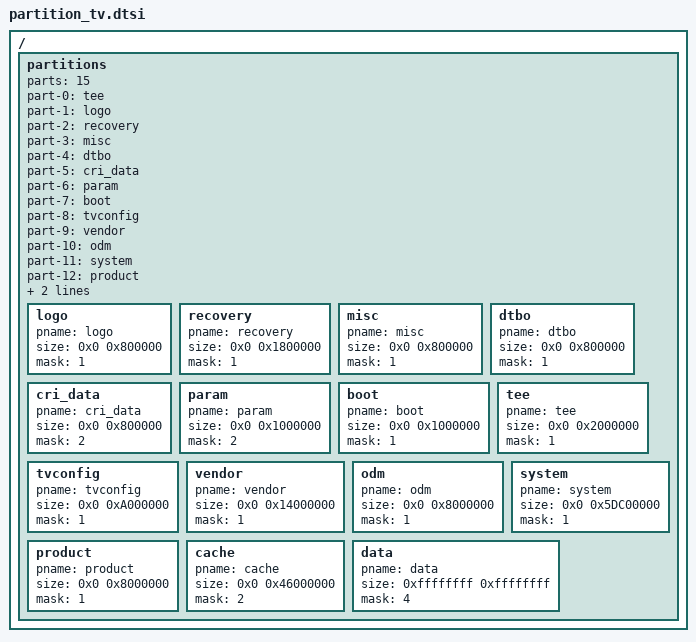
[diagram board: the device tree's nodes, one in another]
/*
 * Amlogic partition set for normal
 *
 * Copyright (c) 2017-2017 Amlogic Ltd
 *
 * This file is licensed under a dual GPLv2 or BSD license.
 *
 */

#include "firmware_system.dtsi"

/ {
    partitions: partitions{
		parts = <15>;
		part-0 = <&tee>;
		part-1 = <&logo>;
		part-2 = <&recovery>;
		part-3 = <&misc>;
		part-4 = <&dtbo>;
		part-5 = <&cri_data>;
		part-6 = <&param>;
		part-7 = <&boot>;
		part-8 = <&tvconfig>;
		part-9 = <&vendor>;
		part-10 = <&odm>;
		part-11 = <&system>;
		part-12 = <&product>;
		part-13 = <&cache>;
		part-14 = <&data>;

		logo:logo{
			pname = "logo";
			size = <0x0 0x800000>;
			mask = <1>;
		};
		recovery:recovery{
			pname = "recovery";
			size = <0x0 0x1800000>;
			mask = <1>;
		};
		misc:misc{
			pname = "misc";
			size = <0x0 0x800000>;
			mask = <1>;
		};
		dtbo:dtbo{
			pname = "dtbo";
			size = <0x0 0x800000>;
			mask = <1>;
		};
		cri_data:cri_data
		{
			pname = "cri_data";
			size = <0x0 0x800000>;
			mask = <2>;
		};

		param:param{
			pname = "param";
			size = <0x0 0x1000000>;
			mask = <2>;
		};
		boot:boot
		{
			pname = "boot";
			size = <0x0 0x1000000>;
			mask = <1>;
		};
		tee:tee{
			pname = "tee";
			size = <0x0 0x2000000>;
			mask = <1>;
		};
		tvconfig:tvconfig{
			pname = "tvconfig";
			size = <0x0 0xA000000>;
			mask = <1>;
		};
		vendor:vendor
		{
			pname = "vendor";
			size = <0x0 0x14000000>;
			mask = <1>;
		};
		odm:odm
		{
			pname = "odm";
			size = <0x0 0x8000000>;
			mask = <1>;
		};
		system:system
		{
			pname = "system";
			size = <0x0 0x5DC00000>;
			mask = <1>;
		};
		product:product{
			pname = "product";
			size = <0x0 0x8000000>;
			mask = <1>;
		};
		cache:cache
		{
			pname = "cache";
			size = <0x0 0x46000000>;
			mask = <2>;
		};
		data:data
		{
			pname = "data";
			size = <0xffffffff 0xffffffff>;
			mask = <4>;
		};
	};
};/* end of / */
